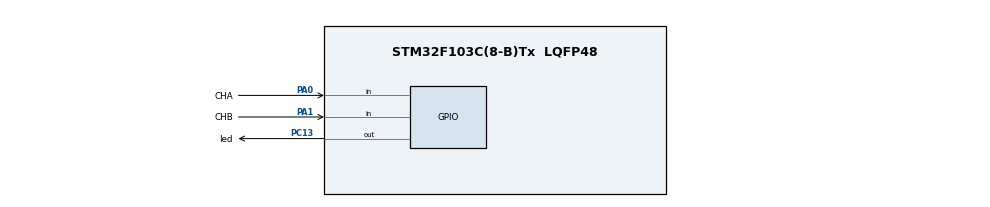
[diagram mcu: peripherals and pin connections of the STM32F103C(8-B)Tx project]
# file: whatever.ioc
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Mcu.Family=STM32F1
Mcu.Name=STM32F103C(8-B)Tx
Mcu.Package=LQFP48
NVIC.PriorityGroup=NVIC_PRIORITYGROUP_4
PA0-WKUP.GPIO_Label=CHA
PA0-WKUP.Signal=GPIO_Input
PA1.GPIO_Label=CHB
PA1.Signal=GPIO_Input
PA13.Mode=Serial_Wire
PA13.Signal=SYS_JTMS-SWDIO
PA14.Mode=Serial_Wire
PA14.Signal=SYS_JTCK-SWCLK
PC13-TAMPER-RTC.GPIO_Label=led
PC13-TAMPER-RTC.Signal=GPIO_Output
PD0-OSC_IN.Mode=HSE-External-Oscillator
PD0-OSC_IN.Signal=RCC_OSC_IN
PD1-OSC_OUT.Mode=HSE-External-Oscillator
PD1-OSC_OUT.Signal=RCC_OSC_OUT
ProjectManager.HeapSize=0x200
ProjectManager.StackSize=0x400
ProjectManager.TargetToolchain=STM32CubeIDE
RCC.AHBFreq_Value=8000000
RCC.APB1CLKDivider=RCC_HCLK_DIV4
RCC.APB1Freq_Value=2000000
RCC.APB1TimFreq_Value=4000000
RCC.APB2Freq_Value=8000000
RCC.APB2TimFreq_Value=8000000
RCC.HCLKFreq_Value=8000000
board=custom

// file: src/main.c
/* USER CODE BEGIN Header */
/**
  ******************************************************************************
  * @file           : main.c
  * @brief          : Main program body
  ******************************************************************************
  * @attention
  *
  * Copyright (c) 2025 STMicroelectronics.
  * All rights reserved.
  *
  * This software is licensed under terms that can be found in the LICENSE file
  * in the root directory of this software component.
  * If no LICENSE file comes with this software, it is provided AS-IS.
  *
  ******************************************************************************
  */
/* USER CODE END Header */
#include "main.h"
#include "time.h"
#include "math.h"

void SystemClock_Config(void);
static void MX_GPIO_Init(void);

/* USER CODE BEGIN 0 */
GPIO_PinState a;
GPIO_PinState b;
int tick = 0.0001;
int flag = 0;
int current =0;
int lockin = 0;
int pos=0;
uint32_t lasttime;
int val;
int t[200];
int angs[200];
float delta_timer;
int prev_pos;
int current_pos;
int timer;
float angular_speed;
int new_timer;
void flagger(uint8_t a, uint8_t b){
	if (a == GPIO_PIN_SET && b == GPIO_PIN_RESET) {
		if(lockin ==0){
			flag = -1;
			lockin=1;
		}
	}
	if (a == GPIO_PIN_SET && b == GPIO_PIN_SET) {
		pos += flag;
		if(pos<0){
			pos=19;
		}if (pos==20){
			pos = 0;
		}
		flag = 0;
		lockin = 0;
	}
	if (a == GPIO_PIN_RESET && b == GPIO_PIN_SET) {
		if(lockin ==0){
			flag = 1;
			lockin=1;
		}
	}
}
/* USER CODE END 0 */

int main(void)
{

  /* MCU Configuration--------------------------------------------------------*/

  /* Reset of all peripherals, Initializes the Flash interface and the Systick. */
  HAL_Init();

  /* Configure the system clock */
  SystemClock_Config();

  /* Initialize all configured peripherals */
  MX_GPIO_Init();

  /* Infinite loop */
  /* USER CODE BEGIN WHILE */
//  uint32_t last_tick = 0;
//  uint32_t current_tick;
//  uint16_t period = 1000;
  while (1)
  {
	  timer = HAL_GetTick();
	  a = HAL_GPIO_ReadPin(CHA_GPIO_Port, CHA_Pin);
	  b = HAL_GPIO_ReadPin(CHB_GPIO_Port, CHB_Pin);
	  prev_pos = pos;
	  flagger(a,b);
	  current_pos = pos;
	  new_timer = HAL_GetTick();
	  if(current_pos!=prev_pos){
		  delta_timer = abs((new_timer - timer));
		  angular_speed = 1000*M_PI/delta_timer;
	  }
    /* USER CODE END WHILE *
//	  val = getvalue(a,b);
//	  current += val;
//	  currentstep = val;
//	  ang= current*(180/20);
//	  if (i%200 ==0){
//		  //print(angle);
//		  angs[i]=ang;
//		  t[i]=current_tick - last_tick;
//		  last_tick = current_tick;
//		  //print(t[i]);
//	  }
//	  i+=1;
//	  HAL_Delay(1);
//	  if (abs(ang)>200*360){
//		  break;
//	  }
  }
}

//int getstep(uint8_t val){
//	if (val == currentstep+1){
//		return 1;
//	}else if (val == currentstep-1){
//		return -1;
//	}else if(val ==1 && currentstep ==4 ){
//		return 1;
//	}else if(val ==4 && currentstep ==1 ){
//		return -1;
//	}
//	return 0;
//}
void SystemClock_Config(void)
{
  RCC_OscInitTypeDef RCC_OscInitStruct = {0};
  RCC_ClkInitTypeDef RCC_ClkInitStruct = {0};

  /** Initializes the RCC Oscillators according to the specified parameters
  * in the RCC_OscInitTypeDef structure.
  */
  RCC_OscInitStruct.OscillatorType = RCC_OSCILLATORTYPE_HSI;
  RCC_OscInitStruct.HSIState = RCC_HSI_ON;
  RCC_OscInitStruct.HSICalibrationValue = RCC_HSICALIBRATION_DEFAULT;
  RCC_OscInitStruct.PLL.PLLState = RCC_PLL_NONE;
  if (HAL_RCC_OscConfig(&RCC_OscInitStruct) != HAL_OK)
  {
    Error_Handler();
  }

  /** Initializes the CPU, AHB and APB buses clocks
  */
  RCC_ClkInitStruct.ClockType = RCC_CLOCKTYPE_HCLK|RCC_CLOCKTYPE_SYSCLK
                              |RCC_CLOCKTYPE_PCLK1|RCC_CLOCKTYPE_PCLK2;
  RCC_ClkInitStruct.SYSCLKSource = RCC_SYSCLKSOURCE_HSI;
  RCC_ClkInitStruct.AHBCLKDivider = RCC_SYSCLK_DIV1;
  RCC_ClkInitStruct.APB1CLKDivider = RCC_HCLK_DIV4;
  RCC_ClkInitStruct.APB2CLKDivider = RCC_HCLK_DIV1;

  if (HAL_RCC_ClockConfig(&RCC_ClkInitStruct, FLASH_LATENCY_0) != HAL_OK)
  {
    Error_Handler();
  }
}

static void MX_GPIO_Init(void)
{
  GPIO_InitTypeDef GPIO_InitStruct = {0};

  /* GPIO Ports Clock Enable */
  __HAL_RCC_GPIOC_CLK_ENABLE();
  __HAL_RCC_GPIOD_CLK_ENABLE();
  __HAL_RCC_GPIOA_CLK_ENABLE();

  /*Configure GPIO pin Output Level */
  HAL_GPIO_WritePin(led_GPIO_Port, led_Pin, GPIO_PIN_RESET);

  /*Configure GPIO pin : led_Pin */
  GPIO_InitStruct.Pin = led_Pin;
  GPIO_InitStruct.Mode = GPIO_MODE_OUTPUT_PP;
  GPIO_InitStruct.Pull = GPIO_NOPULL;
  GPIO_InitStruct.Speed = GPIO_SPEED_FREQ_LOW;
  HAL_GPIO_Init(led_GPIO_Port, &GPIO_InitStruct);

  /*Configure GPIO pins : CHA_Pin CHB_Pin */
  GPIO_InitStruct.Pin = CHA_Pin|CHB_Pin;
  GPIO_InitStruct.Mode = GPIO_MODE_INPUT;
  GPIO_InitStruct.Pull = GPIO_NOPULL;
  HAL_GPIO_Init(GPIOA, &GPIO_InitStruct);

}

void Error_Handler(void)
{
  __disable_irq();
  while (1)
  {
  }
}
